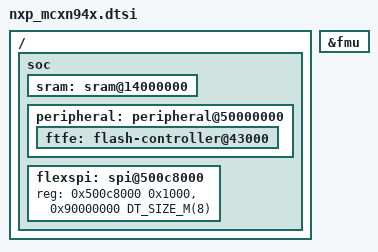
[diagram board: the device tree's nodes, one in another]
/*
 * Copyright 2023 NXP
 *
 * SPDX-License-Identifier: Apache-2.0
 */

#include <mem.h>
#include <arm/armv8-m.dtsi>
#include <zephyr/dt-bindings/gpio/gpio.h>
#include <zephyr/dt-bindings/i2c/i2c.h>

/ {
	soc {
		sram: sram@14000000 {
			ranges = <0x4000000 0x14000000 0x20000000>;
		};

		peripheral: peripheral@50000000 {
			ranges = <0x0 0x50000000 0x10000000>;

			ftfe: flash-controller@43000 {
				ranges = <0x0 0x10000000 0x4000000>;
			};
		};

		flexspi: spi@500c8000 {
			reg = <0x500c8000 0x1000>, <0x90000000 DT_SIZE_M(8)>;
		};
	};
};

#include "nxp_mcxn94x_common.dtsi"

/*
 * Explicitly enable FMU after we include the common dtsi file,
 * which will set it to disabled.
 */
&fmu {
	status = "okay";
};
